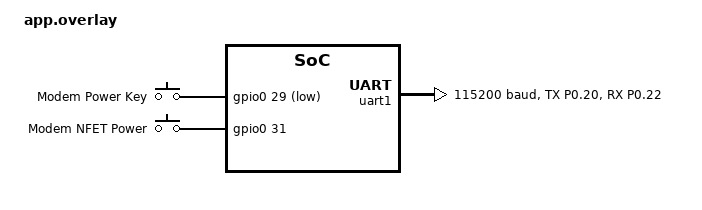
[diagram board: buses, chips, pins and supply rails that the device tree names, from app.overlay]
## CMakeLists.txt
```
cmake_minimum_required(VERSION 3.20.0)

find_package(Zephyr REQUIRED HINTS $ENV{ZEPHYR_BASE})
project(modem_chat_sim7080g)

# 1. Dynamically search the folder for all matching files
file(GLOB CLIENT_CERT_PATH "certificate/*.cert.pem")
file(GLOB CLIENT_KEY_PATH  "certificate/*.key.pem")

# 2. CRITICAL FIX: Filter out "root.cert.pem" so it isn't mistaken for a client cert
list(FILTER CLIENT_CERT_PATH EXCLUDE REGEX "root\\.cert\\.pem")

# 3. Safety Check: Ensure the automation pipeline dropped exactly 1 client certificate
list(LENGTH CLIENT_CERT_PATH cert_count)
if(NOT cert_count EQUAL 1)
    message(FATAL_ERROR "Automation Error: Expected exactly 1 client cert in folder, found: ${cert_count}")
endif()

# 4. Extract the dynamic UUID/Identity from the remaining file
get_filename_component(TMP_NAME ${CLIENT_CERT_PATH} NAME_WE)
get_filename_component(EXTRACTED_UUID ${TMP_NAME} NAME_WE)

# Set up include directory for the generated asset files
set(gen_dir ${CMAKE_CURRENT_BINARY_DIR}/certs)
zephyr_include_directories(${gen_dir})

# 5. Feed the files into the generator (root remains explicit, client uses the dynamic path)
generate_inc_file_for_target(app certificate/root.cert.pem  ${gen_dir}/root.cert.pem.inc)
generate_inc_file_for_target(app ${CLIENT_CERT_PATH}        ${gen_dir}/client.cert.pem.inc)
generate_inc_file_for_target(app ${CLIENT_KEY_PATH}         ${gen_dir}/client.key.pem.inc)

target_sources(app PRIVATE 
    src/main.c 
    src/modem_driver.c
    src/certificates.c
)

target_include_directories(app PRIVATE 
    include
)

# 6. Inject the dynamic string macro straight into your C compilation target
target_compile_definitions(app PRIVATE MQTT_CLIENT_ID="${EXTRACTED_UUID}")

# Status message for verification
message(STATUS ">>> AUTOMATION: Discovered Device Identity: ${EXTRACTED_UUID} <<<")
```

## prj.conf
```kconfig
# --- CONFIGURATION DE BASE ---
CONFIG_GPIO=y
CONFIG_UART_INTERRUPT_DRIVEN=y

# --- STACK ---
CONFIG_MAIN_STACK_SIZE=4096

# --- LOGGING ---
CONFIG_SERIAL=y
CONFIG_LOG=y
CONFIG_LOG_BUFFER_SIZE=4096
CONFIG_LOG_DEFAULT_LEVEL=3
CONFIG_LOG_MODE_DEFERRED=y
CONFIG_LOG_BACKEND_UART=y

# --- BUILD ---
CONFIG_BUILD_OUTPUT_UF2=y
```

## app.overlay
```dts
&pinctrl {
    uart1_default: uart1_default {
        group1 {
            psels = <NRF_PSEL(UART_TX, 0, 20)>;
        };
        group2 {
            psels = <NRF_PSEL(UART_RX, 0, 22)>;
            bias-pull-up;
        };
    };

    uart1_sleep: uart1_sleep {
        group1 {
            psels = <NRF_PSEL(UART_TX, 0, 20)>,
                    <NRF_PSEL(UART_RX, 0, 22)>;
            low-power-enable;
        };
    };
};

&uart1 {
    status = "okay";
    current-speed = <115200>;
    pinctrl-0 = <&uart1_default>;
    pinctrl-1 = <&uart1_sleep>;
    pinctrl-names = "default", "sleep";
};

/ {
    modem_hardware {
        compatible = "gpio-keys";
        
        sim7080_pwrkey: pwr_key_pin {
            gpios = <&gpio0 29 GPIO_ACTIVE_LOW>; 
            label = "Modem Power Key";
        };

        sim7080_nfet: nfet_pin {
            gpios = <&gpio0 31 GPIO_ACTIVE_HIGH>; 
            label = "Modem NFET Power";
        };
    };
};
```

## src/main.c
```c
#include <zephyr/kernel.h>
#include <zephyr/device.h>
#include "modem_driver.h"
#include "certificates.h"
#include "app_config.h"

static modem_ctx_t sim7080_ctx;

int main(void)
{
    char resp[256];
    
    const struct device *uart_dev = DEVICE_DT_GET(DT_NODELABEL(uart1));

    printk("Initializing Cellular Tracker (Context-Based Architecture)...\n");

    if (modem_init(&sim7080_ctx, uart_dev) != 0) {
        printk("Hardware error: UART interface not ready or context binding failed.\n");
        return -1;
    }

    k_sleep(K_SECONDS(2));

    modem_send_command(&sim7080_ctx, "ATE0", resp, sizeof(resp), 2000); 

    modem_send_command(&sim7080_ctx, "AT+CPIN?", resp, sizeof(resp), 3000);
    modem_send_command(&sim7080_ctx, "AT+CSQ", resp, sizeof(resp), 3000);
    modem_send_command(&sim7080_ctx, "AT+CEREG?", resp, sizeof(resp), 3000);
    modem_send_command(&sim7080_ctx, "AT+CGATT=1", resp, sizeof(resp), 10000);
    modem_send_command(&sim7080_ctx, "AT+CGDCONT=1,\"IP\",\"TM\"", resp, sizeof(resp), 5000);
    modem_send_command(&sim7080_ctx, "AT+CNACT?", resp, sizeof(resp), 5000);

    if (modem_provision_and_configure_tls(&sim7080_ctx, 0, 
                                          root_ca, root_ca_len, 
                                          client_cert, client_cert_len, 
                                          client_key, client_key_len) != 0) {
        printk("Boot halted: Secure TLS Provisioning Pipeline Failed.\n");
        return -1;
    }

    printk("\nSYSTEM CONFIGURATION COMPLETE\n");

    if (modem_mqtt_connect(&sim7080_ctx, 
                           MQTT_BROKER_URL, 
                           MQTT_BROKER_PORT, 
                           MQTT_CLIENT_ID, 
                           MQTT_KEEP_ALIVE_SEC, 
                           MQTT_CLEAN_SESSION, 
                           MQTT_SSL_CTX_INDEX) != 0) {
        printk("Network error: MQTT secure handshaking failed.\n");
        return -1;
    }

    int ret = modem_mqtt_publish(&sim7080_ctx, 
                                "tracker/" MQTT_CLIENT_ID "/msg", // Topic: tracker/client_4/msg
                                "hello world",                    // Payload
                                1,                                // QoS 1 (Acknowledged)
                                0);                               // Retain (0 = Do not retain)

    if (ret == 0) {
        printk("Payload successfully sent!\n");
    } else {
        printk("Error: Failed to publish message (Code: %d)\n", ret);
    }

    while (1) {
        k_sleep(K_SECONDS(1));
    }
}
```

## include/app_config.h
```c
#ifndef APP_CONFIG_H
#define APP_CONFIG_H

/* MQTT Broker Network Settings */
#define MQTT_BROKER_URL       "solanix.fr"
#define MQTT_BROKER_PORT      8883
#define MQTT_KEEP_ALIVE_SEC   60
#define MQTT_CLEAN_SESSION    1

/* Security Routing */
#define MQTT_SSL_CTX_INDEX    0  // Ties directly to the secure profile we provisioned

// NOTE: MQTT_CLIENT_ID is omitted here because it is automatically 
// injected at compile-time by CMake based on your certificate filename!

#endif // APP_CONFIG_H
```

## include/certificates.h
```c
#ifndef CERTIFICATES_H
#define CERTIFICATES_H

#include <stddef.h>

extern const unsigned char root_ca[];
extern const size_t root_ca_len;
extern const unsigned char client_cert[];
extern const size_t client_cert_len;
extern const unsigned char client_key[];
extern const size_t client_key_len;

#endif
```

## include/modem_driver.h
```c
/**
 * @file modem_driver.c
 * @brief SIM7080 modem driver implementation using Zephyr UART IRQ + message queue.
 *
 * Provides AT-command abstraction, TLS provisioning, MQTT connectivity,
 * and file system operations over UART-based modem interface.
 */
#ifndef MODEM_DRIVER_H
#define MODEM_DRIVER_H

#include <zephyr/device.h>
#include <zephyr/kernel.h>
#include <stddef.h>
#include <stdint.h>

#define MODEM_RX_QUEUE_SIZE 1024

/** @brief Modem runtime instance context */
typedef struct {
    const struct device *uart_dev;              /* Tied hardware peripheral instance */
    struct k_msgq rx_msgq;                     /* Instance isolated message queue */
    uint8_t rx_queue_buffer[MODEM_RX_QUEUE_SIZE]; /* Memory backing for the queue */
    struct k_mutex lock;                        /* Protects the modem from multi-threaded overlap */
} modem_ctx_t;

/**
 * @brief Initialize modem driver instance.
 *
 * Configures UART, message queue, mutex, and interrupts.
 *
 * @param ctx Modem context instance
 * @param uart_device UART device pointer from device tree
 *
 * @return 0 on success, -ENODEV if UART not ready
 */
int modem_init(modem_ctx_t *ctx, const struct device *uart_device);

/**
 * @brief Send AT command and wait for response.
 *
 * Thread-safe function protected by mutex.
 *
 * @param ctx Modem context instance
 * @param cmd AT command string
 * @param resp Response buffer
 * @param resp_size Size of response buffer
 * @param timeout_ms Timeout in milliseconds
 *
 * @return 0 on success, -EIO or -ETIMEDOUT on failure
 */
int modem_send_command(modem_ctx_t *ctx, const char *cmd, char *resp, size_t resp_size, int timeout_ms);

/**
 * @brief Write file to modem filesystem.
 *
 * Splits data into chunks and streams via AT+CFSWFILE.
 *
 * @param ctx Modem context
 * @param index File storage index
 * @param filename Target filename on modem
 * @param data File data buffer
 * @param length Length of file data
 * @param cert_type Certificate type (root/client/key)
 *
 * @return 0 on success, negative error code on failure
 */
int modem_write_file(modem_ctx_t *ctx, int index, const char *filename, const uint8_t *data, size_t length, int cert_type);

/**
 * @brief Provision TLS credentials into modem.
 *
 * Uploads CA, client cert, and private key, then configures SSL context.
 *
 * @param ctx Modem context
 * @param ssl_idx SSL context index
 * @param root_ca Root CA certificate
 * @param root_ca_len Length of root CA
 * @param client_cert Client certificate
 * @param client_cert_len Length of client cert
 * @param client_key Private key
 * @param client_key_len Length of private key
 *
 * @return 0 on success, negative error code on failure
 */
int modem_provision_and_configure_tls(modem_ctx_t *ctx, int ssl_idx,
                                      const uint8_t *root_ca, size_t root_ca_len,
                                      const uint8_t *client_cert, size_t client_cert_len,
                                      const uint8_t *client_key, size_t client_key_len);

/**
 * @brief Connect modem to MQTT broker over TLS.
 *
 * Configures broker, client ID, keepalive, session, and SSL profile.
 *
 * @param ctx Modem context
 * @param url Broker URL
 * @param port Broker port
 * @param client_id MQTT client ID
 * @param keepalive Keepalive interval in seconds
 * @param clean_session Clean session flag
 * @param ssl_idx SSL context index
 *
 * @return 0 on success, negative error code on failure
 */
int modem_mqtt_connect(modem_ctx_t *ctx, const char *url, int port, 
                       const char *client_id, int keepalive, 
                       int clean_session, int ssl_idx);

/**
 * @brief Publish MQTT message.
 *
 * Sends payload using AT+SMPUB with QoS and retain flags.
 *
 * @param ctx Modem context
 * @param topic MQTT topic
 * @param payload Message payload
 * @param qos Quality of service level
 * @param retain Retain flag
 *
 * @return 0 on success, negative error code on failure
 */
int modem_mqtt_publish(modem_ctx_t *ctx, const char *topic, 
                       const char *payload, int qos, int retain);

/**
 * @brief Disconnect MQTT session.
 *
 * @param ctx Modem context
 *
 * @return 0 on success, negative error code on failure
 */
int modem_mqtt_disconnect(modem_ctx_t *ctx);

#endif
```

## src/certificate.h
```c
static const unsigned char root_ca[] = {
    #include "root.cert.pem.inc"
};

static const unsigned char client_cert[] = {
    #include "client.cert.pem.inc"
};

static const unsigned char client_key[] = {
    #include "client.key.pem.inc"
};
```

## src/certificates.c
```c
#include "certificates.h"

const unsigned char root_ca[] = {
#include "root.cert.pem.inc"
};
const size_t root_ca_len = sizeof(root_ca) - 1;

const unsigned char client_cert[] = {
#include "client.cert.pem.inc"
};
const size_t client_cert_len = sizeof(client_cert) - 1;

const unsigned char client_key[] = {
#include "client.key.pem.inc"
};
const size_t client_key_len = sizeof(client_key) - 1;
```

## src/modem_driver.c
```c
#include <zephyr/kernel.h>
#include <zephyr/device.h>
#include <zephyr/drivers/uart.h>
#include <zephyr/logging/log.h>

#include <string.h>
#include <stdio.h>
#include <errno.h>

#include "modem_driver.h"

LOG_MODULE_REGISTER(modem_driver, LOG_LEVEL_DBG);

/* =========================================================
 * HARDWARE INTERRUPT SERVICE ROUTINE (ISR)
 * ========================================================= */
static void uart_isr(const struct device *dev, void *user_data) 
{
    /* Cast user_data back to our specific modem context instance */
    modem_ctx_t *ctx = (modem_ctx_t *)user_data;
    if (!ctx) return;

    uart_irq_update(dev);

    if (uart_irq_rx_ready(dev)) {
        uint8_t c;
        while (uart_fifo_read(dev, &c, 1) == 1) {
            /* Feed the byte into this specific instance's queue */
            k_msgq_put(&ctx->rx_msgq, &c, K_NO_WAIT);
        }
    }
}

/* =========================================================
 * PRIVATE INSTANCE UTILITIES
 * ========================================================= */
static void uart_send(modem_ctx_t *ctx, const char *cmd) 
{
    for (int i = 0; cmd[i] != '\0'; i++) {
        uart_poll_out(ctx->uart_dev, cmd[i]);
    }
    uart_poll_out(ctx->uart_dev, '\r');
    uart_poll_out(ctx->uart_dev, '\n');
}

static void uart_write_raw(modem_ctx_t *ctx, const uint8_t *data, size_t len) 
{
    for (size_t i = 0; i < len; i++) {
        uart_poll_out(ctx->uart_dev, data[i]);
    }
}

static void uart_clear_buffers(modem_ctx_t *ctx) 
{
    uint8_t dummy;
    k_msgq_purge(&ctx->rx_msgq);
    while (k_msgq_get(&ctx->rx_msgq, &dummy, K_NO_WAIT) == 0);

    LOG_DBG("RX buffer cleared");
}

static int wait_for_response(modem_ctx_t *ctx, const char *token, char *resp, size_t resp_size, int timeout_ms) 
{
    if (resp && resp_size > 0) memset(resp, 0, resp_size);
    size_t pos = 0;
    uint8_t c;
    int64_t end_time = k_uptime_get() + timeout_ms;

    while (k_uptime_get() < end_time) {
        int64_t remaining = end_time - k_uptime_get();
        if (remaining <= 0) break;

        /* Pop bytes out of our specific instance context queue */
        if (k_msgq_get(&ctx->rx_msgq, &c, K_MSEC(remaining)) == 0) {
            if (resp && pos < resp_size - 1) {
                resp[pos++] = c;
                resp[pos] = 0;
            }
            if (resp && strstr(resp, token)) {
                LOG_DBG("RX matched token: %s", token);
                return 0;
            }
        }
    }
    LOG_WRN("Timeout waiting for token: %s", token);
    return -ETIMEDOUT;
}

/* =========================================================
 * PUBLIC DRIVER API IMPLEMENTATION
 * ========================================================= */
int modem_init(modem_ctx_t *ctx, const struct device *uart_device) 
{
    if (!ctx || !device_is_ready(uart_device)) return -ENODEV;

    ctx->uart_dev = uart_device;

    /* Initialize core synchronization primitives dynamically inside the structure container */
    k_mutex_init(&ctx->lock);
    k_msgq_init(&ctx->rx_msgq, ctx->rx_queue_buffer, sizeof(uint8_t), MODEM_RX_QUEUE_SIZE);

    /* Bind the interrupt handler and securely pass the context address down as user data */
    uart_irq_callback_user_data_set(ctx->uart_dev, uart_isr, ctx);
    uart_irq_rx_enable(ctx->uart_dev);

    return 0;
}

int modem_send_command(modem_ctx_t *ctx,
                       const char *cmd,
                       char *resp,
                       size_t resp_size,
                       int timeout_ms)
{
    int ret;

    k_mutex_lock(&ctx->lock, K_FOREVER);

    uart_clear_buffers(ctx);
    uart_send(ctx, cmd);

    ret = wait_for_response(ctx, "OK", resp, resp_size, timeout_ms);

    if (ret != 0 && resp && strstr(resp, "ERROR")) {
        LOG_ERR("Modem returned ERROR: %s", resp);
        ret = -EIO;
    }

    k_mutex_unlock(&ctx->lock);
    return ret;
}

int modem_write_file(modem_ctx_t *ctx,
                     int index,
                     const char *filename,
                     const uint8_t *data,
                     size_t length,
                     int cert_type)
{
    ARG_UNUSED(cert_type);

    static char resp[256];

    k_mutex_lock(&ctx->lock, K_FOREVER);

    LOG_INF("Writing file %s (%u bytes)", filename, (unsigned int)length);

    if (modem_send_command(ctx, "AT+CFSINIT", resp, sizeof(resp), 5000) != 0) {

        LOG_WRN("CFSINIT failed, attempting CFSTERM recovery");

        modem_send_command(ctx, "AT+CFSTERM", resp, sizeof(resp), 3000);

        if (modem_send_command(ctx, "AT+CFSINIT", resp, sizeof(resp), 5000) != 0) {
            LOG_ERR("CFSINIT recovery failed");
            k_mutex_unlock(&ctx->lock);
            return -EIO;
        }
    }

    size_t remaining = length;
    size_t offset = 0;

    while (remaining > 0) {

        size_t chunk = MIN(remaining, 1024);
        char cmd[128];
        int mode = (offset == 0) ? 0 : 1;

        snprintf(cmd, sizeof(cmd),
                 "AT+CFSWFILE=%d,\"%s\",%d,%u,10000",
                 index, filename, mode, (unsigned int)chunk);

        k_sleep(K_MSEC(30));
        uart_clear_buffers(ctx);

        uart_send(ctx, cmd);

        if (wait_for_response(ctx, "DOWNLOAD",
                               resp, sizeof(resp), 5000) != 0) {

            LOG_ERR("DOWNLOAD prompt timeout");
            modem_send_command(ctx, "AT+CFSTERM", resp, sizeof(resp), 3000);
            k_mutex_unlock(&ctx->lock);
            return -ETIMEDOUT;
        }

        uart_write_raw(ctx, data + offset, chunk);

        if (wait_for_response(ctx, "OK",
                               resp, sizeof(resp), 15000) != 0) {

            LOG_ERR("File write failed at offset %u", (unsigned int)offset);
            modem_send_command(ctx, "AT+CFSTERM", resp, sizeof(resp), 3000);
            k_mutex_unlock(&ctx->lock);
            return -EIO;
        }

        offset += chunk;
        remaining -= chunk;
    }

    LOG_INF("File upload complete");
    modem_send_command(ctx, "AT+CFSTERM", resp, sizeof(resp), 5000);

    k_mutex_unlock(&ctx->lock);
    return 0;
}

int modem_provision_and_configure_tls(modem_ctx_t *ctx, int ssl_idx,
                                      const uint8_t *root_ca, size_t root_ca_len,
                                      const uint8_t *client_cert, size_t client_cert_len,
                                      const uint8_t *client_key, size_t client_key_len)
{
    char cmd[128];
    char resp[128];
    int ret;

    LOG_INF("Provisioning TLS stack");

    /* Step 1: Upload the Root CA certificate to the modem's filesystem */
    ret = modem_write_file(ctx, 3, "ca.pem", root_ca, root_ca_len, 2);
    if (ret != 0) {
        LOG_ERR("Root CA provisioning failed");
        return ret;
    }

    /* Step 2: Upload the Client Certificate to the modem's filesystem */
    ret = modem_write_file(ctx, 3, "cert.pem", client_cert, client_cert_len, 1);
    if (ret != 0) {
        LOG_ERR("TLS Error: Failed to flash Client Certificate");
        return ret;
    }

    /* Step 3: Upload the Client Private Key to the modem's filesystem */
    ret = modem_write_file(ctx, 3, "key.pem", client_key, client_key_len, 4);
    if (ret != 0) {
        LOG_ERR("TLS Error: Failed to flash Client Private Key");
        return ret;
    }

    snprintf(cmd, sizeof(cmd), "AT+CSSLCFG=\"sslversion\",%d,3", ssl_idx);
    ret = modem_send_command(ctx, cmd, resp, sizeof(resp), 2000);
    if (ret != 0) return ret;

    ret = modem_send_command(ctx, "AT+CSSLCFG=\"CONVERT\",2,\"root_ca.pem\"", resp, sizeof(resp), 2000);
    if (ret != 0) return ret;

    ret = modem_send_command(ctx, "AT+CSSLCFG=\"CONVERT\",1,\"client_cert.pem\",\"client_key.pem\"", resp, sizeof(resp), 2000);
    if (ret != 0) return ret;

    ret = modem_send_command(ctx, "AT+SMSSL=1,\"root_ca.pem\",\"client_cert.pem\"", resp, sizeof(resp), 2000);
    if (ret != 0) return ret;

    LOG_INF("TLS provisioning complete");
    return 0;
}

int modem_mqtt_connect(modem_ctx_t *ctx, const char *url, int port, 
                       const char *client_id, int keepalive, 
                       int clean_session, int ssl_idx)
{
    char cmd[128];
    char resp[128];
    int ret;

    LOG_INF("Starting MQTT connection setup");
    
    /* Lock the entire configuration bundle sequence */
    k_mutex_lock(&ctx->lock, K_FOREVER);

    /* =========================================================
     * STEP 0: Check if MQTT is already connected (+SMSTATE: 1)
     * ========================================================= */
    uart_clear_buffers(ctx);
    uart_send(ctx, "AT+SMSTATE?");
    
    /* Expect an 'OK' response, but we must parse the payload buffer */
    ret = wait_for_response(ctx, "OK", resp, sizeof(resp), 2000);
    if (ret == 0) {
        /* If the response contains "+SMSTATE: 1", the connection is alive */
        if (strstr(resp, "+SMSTATE: 1")) {
            LOG_INF("MQTT session is already open. Skipping reconnection.");
            ret = 0; 
            goto unlock_and_exit;
        }
        LOG_DBG("MQTT not connected (State response: %s). Proceeding.", resp);
    } else {
        LOG_WRN("Failed to read MQTT state, attempting normal connection flow.");
    }

    // 1. Set Broker URL and Port
    snprintf(cmd, sizeof(cmd), "AT+SMCONF=\"URL\",\"%s\",%d", url, port);
    ret = modem_send_command(ctx, cmd, resp, sizeof(resp), 2000);
    if (ret != 0) goto unlock_and_exit;

    // 2. Set Client ID
    snprintf(cmd, sizeof(cmd), "AT+SMCONF=\"CLIENTID\",\"%s\"", client_id);
    ret = modem_send_command(ctx, cmd, resp, sizeof(resp), 2000);
    if (ret != 0) goto unlock_and_exit;

    // 3. Set Keepalive Interval
    snprintf(cmd, sizeof(cmd), "AT+SMCONF=\"KEEPTIME\",%d", keepalive);
    ret = modem_send_command(ctx, cmd, resp, sizeof(resp), 2000);
    if (ret != 0) goto unlock_and_exit;

    // 4. Set Clean Session Flag
    snprintf(cmd, sizeof(cmd), "AT+SMCONF=\"CLEANSS\",%d", clean_session);
    ret = modem_send_command(ctx, cmd, resp, sizeof(resp), 2000);
    if (ret != 0) goto unlock_and_exit;

    // 5. Execute Connection Request (Allow up to 30 seconds for TLS Handshake)
    LOG_INF("Connecting to broker (TLS handshake)");
    
    /* Note: Increased timeout here slightly because your comment mentions 
       30 seconds, but your original code only gave it 3000ms (3 seconds). */
    ret = modem_send_command(ctx, "AT+SMCONN", resp, sizeof(resp), 30000);

unlock_and_exit:
    k_mutex_unlock(&ctx->lock);
    return ret;
}

int modem_mqtt_publish(modem_ctx_t *ctx, const char *topic, 
                       const char *payload, int qos, int retain)
{
    char cmd[128];
    char resp[128];
    size_t payload_len = strlen(payload);
    int ret;

    k_mutex_lock(&ctx->lock, K_FOREVER);

    // 1. Send the Publish request with exact payload length verification
    snprintf(cmd, sizeof(cmd), "AT+SMPUB=\"%s\",%u,%d,%d", 
             topic, (unsigned int)payload_len, qos, retain);
    
    uart_clear_buffers(ctx);
    LOG_DBG("MQTT publish topic=%s", topic);
    LOG_DBG("Payload len=%u", (unsigned)payload_len);
    
    // Explicit low-level write to handle step-by-step handshake
    for (int i = 0; cmd[i] != '\0'; i++) uart_poll_out(ctx->uart_dev, cmd[i]);
    uart_poll_out(ctx->uart_dev, '\r');
    uart_poll_out(ctx->uart_dev, '\n');

    // 2. Wait for the modem to present the data input prompt ('>')
    ret = wait_for_response(ctx, ">", resp, sizeof(resp), 5000);
    if (ret != 0) {
        LOG_ERR("Error: Modem did not present '>' data prompt.");
        goto publish_exit;
    }

    // 3. Stream raw payload text directly behind the prompt
    LOG_DBG("Streaming publication payload: %s", payload);
    for (size_t i = 0; i < payload_len; i++) {
        uart_poll_out(ctx->uart_dev, payload[i]);
    }

    // 4. Verify acknowledgment from the broker
    ret = wait_for_response(ctx, "OK", resp, sizeof(resp), 10000);
    if (ret != 0) {
        LOG_ERR("Error: Publication handshake acknowledgement failed.");
    }

publish_exit:
    k_mutex_unlock(&ctx->lock);
    return ret;
}

int modem_mqtt_disconnect(modem_ctx_t *ctx)
{
    char resp[64];
    return modem_send_command(ctx, "AT+SMDISC", resp, sizeof(resp), 5000);
}
```
